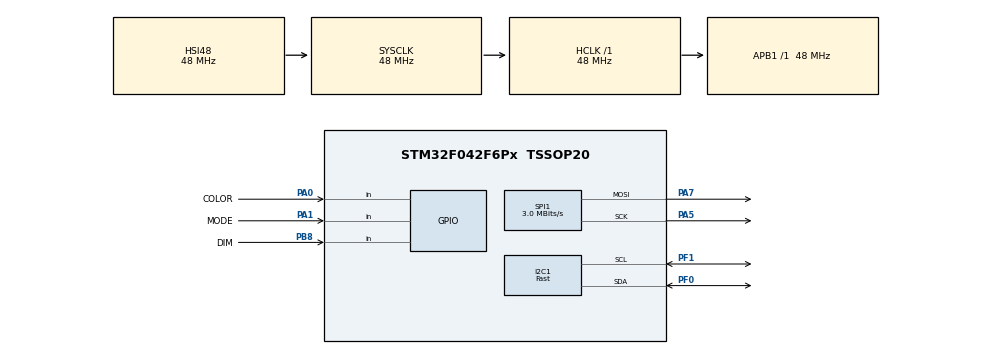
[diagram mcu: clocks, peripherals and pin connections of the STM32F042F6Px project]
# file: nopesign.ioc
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Dma.Request0=SPI1_TX
Dma.SPI1_TX.0.Direction=DMA_MEMORY_TO_PERIPH
Dma.SPI1_TX.0.Instance=DMA1_Channel3
Dma.SPI1_TX.0.MemDataAlignment=DMA_MDATAALIGN_HALFWORD
Dma.SPI1_TX.0.MemInc=DMA_MINC_ENABLE
Dma.SPI1_TX.0.Mode=DMA_NORMAL
Dma.SPI1_TX.0.PeriphDataAlignment=DMA_PDATAALIGN_HALFWORD
Dma.SPI1_TX.0.PeriphInc=DMA_PINC_DISABLE
Dma.SPI1_TX.0.Priority=DMA_PRIORITY_LOW
I2C1.Analog_Filter=I2C_ANALOGFILTER_ENABLE
I2C1.I2C_Speed_Mode=I2C_Fast
I2C1.Timing=0x0000020B
Mcu.Family=STM32F0
Mcu.Name=STM32F042F6Px
Mcu.Package=TSSOP20
NVIC.DMA1_Channel2_3_IRQn=true\:0\:0\:false\:false\:true\:true\:true\:true
NVIC.TIM14_IRQn=true\:0\:0\:false\:false\:true\:true\:true\:true
PA0.GPIO_Label=COLOR
PA0.GPIO_PuPd=GPIO_PULLUP
PA0.Signal=GPIO_Input
PA1.GPIO_Label=MODE
PA1.GPIO_PuPd=GPIO_PULLUP
PA1.Signal=GPIO_Input
PA13.Mode=Serial_Wire
PA13.Signal=SYS_SWDIO
PA14.Mode=Serial_Wire
PA14.Signal=SYS_SWCLK
PA5.Mode=TX_Only_Simplex_Unidirect_Master
PA5.Signal=SPI1_SCK
PA7.Mode=TX_Only_Simplex_Unidirect_Master
PA7.Signal=SPI1_MOSI
PB8.GPIO_Label=DIM
PB8.GPIO_PuPd=GPIO_PULLUP
PB8.Signal=GPIO_Input
PF0-OSC_IN.Mode=I2C
PF0-OSC_IN.Signal=I2C1_SDA
PF1-OSC_OUT.Mode=I2C
PF1-OSC_OUT.Signal=I2C1_SCL
ProjectManager.HeapSize=0x200
ProjectManager.StackSize=0x400
ProjectManager.TargetToolchain=STM32CubeIDE
RCC.AHBFreq_Value=48000000
RCC.APB1Freq_Value=48000000
RCC.APB1TimFreq_Value=48000000
RCC.HCLKFreq_Value=48000000
RCC.SYSCLKFreq_VALUE=48000000
RCC.SYSCLKSource=RCC_SYSCLKSOURCE_HSI48
SPI1.BaudRatePrescaler=SPI_BAUDRATEPRESCALER_16
SPI1.CalculateBaudRate=3.0 MBits/s
SPI1.DataSize=SPI_DATASIZE_16BIT
SPI1.Direction=SPI_DIRECTION_2LINES
SPI1.Mode=SPI_MODE_MASTER
SPI1.NSSPMode=SPI_NSS_PULSE_DISABLE
SPI1.VirtualType=VM_MASTER
TIM14.AutoReloadPreload=TIM_AUTORELOAD_PRELOAD_DISABLE
TIM14.Period=3124
TIM14.Prescaler=255
VP_SYS_VS_PINREMAP.Mode=PINREMAP
VP_TIM14_VS_ClockSourceINT.Mode=Enable_Timer
board=custom

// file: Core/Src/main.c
/* USER CODE BEGIN Header */
/**
  ******************************************************************************
  * @file           : main.c
  * @brief          : Main program body
  ******************************************************************************
  * @attention
  *
  * Copyright (c) 2023 STMicroelectronics.
  * All rights reserved.
  *
  * This software is licensed under terms that can be found in the LICENSE file
  * in the root directory of this software component.
  * If no LICENSE file comes with this software, it is provided AS-IS.
  *
  ******************************************************************************
  */
/* USER CODE END Header */
#include "main.h"

/* USER CODE BEGIN Includes */
#include "display.h"
#include "modes_colors.h"
#include "dfu_jump.h"
/* USER CODE END Includes */

I2C_HandleTypeDef hi2c1;

SPI_HandleTypeDef hspi1;
DMA_HandleTypeDef hdma_spi1_tx;

TIM_HandleTypeDef htim14;

void SystemClock_Config(void);
static void MX_GPIO_Init(void);
static void MX_DMA_Init(void);
static void MX_SPI1_Init(void);
static void MX_TIM14_Init(void);
static void MX_I2C1_Init(void);

int main(void)
{

  /* MCU Configuration--------------------------------------------------------*/

  /* Reset of all peripherals, Initializes the Flash interface and the Systick. */
  HAL_Init();

  /* Configure the system clock */
  SystemClock_Config();

  /* Initialize all configured peripherals */
  MX_GPIO_Init();
  MX_DMA_Init();
  MX_SPI1_Init();
  MX_TIM14_Init();
  MX_I2C1_Init();
  /* USER CODE BEGIN 2 */

  // check if DIM/MODE is held low, jump to bootloader if it is
  // this requires BOOTSEL=0 in option bits
  if (HAL_GPIO_ReadPin(GPIOB, GPIO_PIN_8) == 0) {
	  dfu_jump();
  }

  /* USER CODE END 2 */

  /* Infinite loop */
  while (1)
  {

    /* USER CODE BEGIN 3 */
	  display_init();
	  modes_run();
  }
  /* USER CODE END 3 */
}

void SystemClock_Config(void)
{
  RCC_OscInitTypeDef RCC_OscInitStruct = {0};
  RCC_ClkInitTypeDef RCC_ClkInitStruct = {0};
  RCC_PeriphCLKInitTypeDef PeriphClkInit = {0};

  /** Initializes the RCC Oscillators according to the specified parameters
  * in the RCC_OscInitTypeDef structure.
  */
  RCC_OscInitStruct.OscillatorType = RCC_OSCILLATORTYPE_HSI|RCC_OSCILLATORTYPE_HSI48;
  RCC_OscInitStruct.HSIState = RCC_HSI_ON;
  RCC_OscInitStruct.HSI48State = RCC_HSI48_ON;
  RCC_OscInitStruct.HSICalibrationValue = RCC_HSICALIBRATION_DEFAULT;
  RCC_OscInitStruct.PLL.PLLState = RCC_PLL_NONE;
  if (HAL_RCC_OscConfig(&RCC_OscInitStruct) != HAL_OK)
  {
    Error_Handler();
  }

  /** Initializes the CPU, AHB and APB buses clocks
  */
  RCC_ClkInitStruct.ClockType = RCC_CLOCKTYPE_HCLK|RCC_CLOCKTYPE_SYSCLK
                              |RCC_CLOCKTYPE_PCLK1;
  RCC_ClkInitStruct.SYSCLKSource = RCC_SYSCLKSOURCE_HSI48;
  RCC_ClkInitStruct.AHBCLKDivider = RCC_SYSCLK_DIV1;
  RCC_ClkInitStruct.APB1CLKDivider = RCC_HCLK_DIV1;

  if (HAL_RCC_ClockConfig(&RCC_ClkInitStruct, FLASH_LATENCY_1) != HAL_OK)
  {
    Error_Handler();
  }
  PeriphClkInit.PeriphClockSelection = RCC_PERIPHCLK_I2C1;
  PeriphClkInit.I2c1ClockSelection = RCC_I2C1CLKSOURCE_HSI;
  if (HAL_RCCEx_PeriphCLKConfig(&PeriphClkInit) != HAL_OK)
  {
    Error_Handler();
  }
}

static void MX_I2C1_Init(void)
{

  hi2c1.Instance = I2C1;
  hi2c1.Init.Timing = 0x0000020B;
  hi2c1.Init.OwnAddress1 = 0;
  hi2c1.Init.AddressingMode = I2C_ADDRESSINGMODE_7BIT;
  hi2c1.Init.DualAddressMode = I2C_DUALADDRESS_DISABLE;
  hi2c1.Init.OwnAddress2 = 0;
  hi2c1.Init.OwnAddress2Masks = I2C_OA2_NOMASK;
  hi2c1.Init.GeneralCallMode = I2C_GENERALCALL_DISABLE;
  hi2c1.Init.NoStretchMode = I2C_NOSTRETCH_DISABLE;
  if (HAL_I2C_Init(&hi2c1) != HAL_OK)
  {
    Error_Handler();
  }

  /** Configure Analogue filter
  */
  if (HAL_I2CEx_ConfigAnalogFilter(&hi2c1, I2C_ANALOGFILTER_ENABLE) != HAL_OK)
  {
    Error_Handler();
  }

  /** Configure Digital filter
  */
  if (HAL_I2CEx_ConfigDigitalFilter(&hi2c1, 0) != HAL_OK)
  {
    Error_Handler();
  }

}

static void MX_SPI1_Init(void)
{

  /* SPI1 parameter configuration*/
  hspi1.Instance = SPI1;
  hspi1.Init.Mode = SPI_MODE_MASTER;
  hspi1.Init.Direction = SPI_DIRECTION_2LINES;
  hspi1.Init.DataSize = SPI_DATASIZE_16BIT;
  hspi1.Init.CLKPolarity = SPI_POLARITY_LOW;
  hspi1.Init.CLKPhase = SPI_PHASE_1EDGE;
  hspi1.Init.NSS = SPI_NSS_SOFT;
  hspi1.Init.BaudRatePrescaler = SPI_BAUDRATEPRESCALER_16;
  hspi1.Init.FirstBit = SPI_FIRSTBIT_MSB;
  hspi1.Init.TIMode = SPI_TIMODE_DISABLE;
  hspi1.Init.CRCCalculation = SPI_CRCCALCULATION_DISABLE;
  hspi1.Init.CRCPolynomial = 7;
  hspi1.Init.CRCLength = SPI_CRC_LENGTH_DATASIZE;
  hspi1.Init.NSSPMode = SPI_NSS_PULSE_DISABLE;
  if (HAL_SPI_Init(&hspi1) != HAL_OK)
  {
    Error_Handler();
  }

}

static void MX_TIM14_Init(void)
{

  htim14.Instance = TIM14;
  htim14.Init.Prescaler = 255;
  htim14.Init.CounterMode = TIM_COUNTERMODE_UP;
  htim14.Init.Period = 3124;
  htim14.Init.ClockDivision = TIM_CLOCKDIVISION_DIV1;
  htim14.Init.AutoReloadPreload = TIM_AUTORELOAD_PRELOAD_DISABLE;
  if (HAL_TIM_Base_Init(&htim14) != HAL_OK)
  {
    Error_Handler();
  }

}

static void MX_DMA_Init(void)
{

  /* DMA controller clock enable */
  __HAL_RCC_DMA1_CLK_ENABLE();

  /* DMA interrupt init */
  /* DMA1_Channel2_3_IRQn interrupt configuration */
  HAL_NVIC_SetPriority(DMA1_Channel2_3_IRQn, 0, 0);
  HAL_NVIC_EnableIRQ(DMA1_Channel2_3_IRQn);

}

static void MX_GPIO_Init(void)
{
  GPIO_InitTypeDef GPIO_InitStruct = {0};

  /* GPIO Ports Clock Enable */
  __HAL_RCC_GPIOB_CLK_ENABLE();
  __HAL_RCC_GPIOF_CLK_ENABLE();
  __HAL_RCC_GPIOA_CLK_ENABLE();

  /*Configure GPIO pin : DIM_Pin */
  GPIO_InitStruct.Pin = DIM_Pin;
  GPIO_InitStruct.Mode = GPIO_MODE_INPUT;
  GPIO_InitStruct.Pull = GPIO_PULLUP;
  HAL_GPIO_Init(DIM_GPIO_Port, &GPIO_InitStruct);

  /*Configure GPIO pins : COLOR_Pin MODE_Pin */
  GPIO_InitStruct.Pin = COLOR_Pin|MODE_Pin;
  GPIO_InitStruct.Mode = GPIO_MODE_INPUT;
  GPIO_InitStruct.Pull = GPIO_PULLUP;
  HAL_GPIO_Init(GPIOA, &GPIO_InitStruct);

}

void Error_Handler(void)
{
  __disable_irq();
  while (1)
  {
  }
}
